# RL6845_IP_SVD register map
Vendor: Realtek
Registers are 32-bit, read-write, reset 0x0 unless marked. A register's access mark holds for its fields unless they carry their own. Offsets are from the block's base; [hi:lo] are bit positions.

## page2
Base 0x40000000
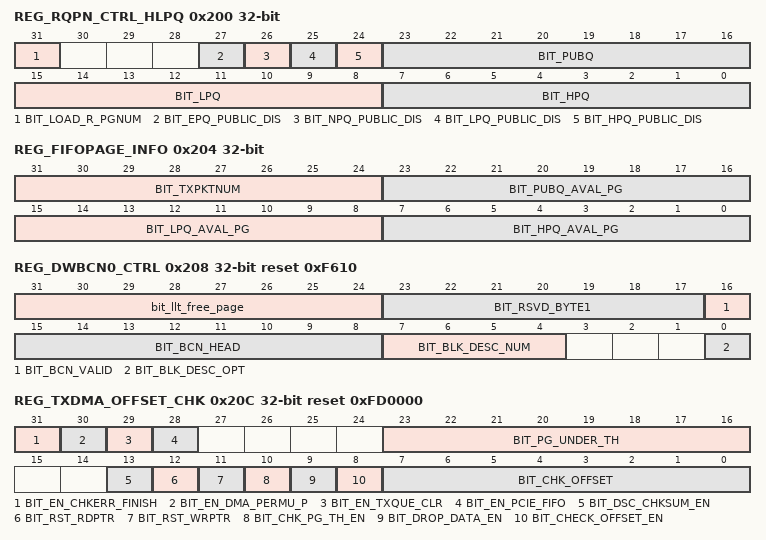
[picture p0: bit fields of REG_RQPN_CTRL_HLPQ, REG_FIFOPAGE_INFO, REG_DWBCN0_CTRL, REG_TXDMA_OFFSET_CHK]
0x200 REG_RQPN_CTRL_HLPQ access per field
  [31] BIT_LOAD_R_PGNUM wo — Write 1 to set RQPN bit[79:0] value to page numbers for initialization
  [27] BIT_EPQ_PUBLIC_DIS rw — When this bit is set, Extra queue available Tx page size excludes the public queue. Otherwise, Extra queue available Tx page size includes public queue
  [26] BIT_NPQ_PUBLIC_DIS rw — When this bit is set, Normal queue available Tx page size excludes the public queue. Otherwise, Normal queue available Tx page size includes public queue
  [25] BIT_LPQ_PUBLIC_DIS rw — When this bit is set, Low queue available Tx page size excludes the public queue. Otherwise, Low queue available Tx page size includes public queue
  [24] BIT_HPQ_PUBLIC_DIS rw — When this bit is set, High queue available Tx page size excludes the public queue. Otherwise, High queue available Tx page size includes public queue
  [23:16] BIT_PUBQ rw — Public Reserved Page Number
  [15:8] BIT_LPQ rw — Low Priority Queue Reserved Page Number
  [7:0] BIT_HPQ rw — High Priority Queue Reserved Page Number
0x204 REG_FIFOPAGE_INFO ro
  [31:24] BIT_TXPKTNUM — Packet number in TXPKTBUF (Normal/Low)
  [23:16] BIT_PUBQ_AVAL_PG — Available Public Queue Page Number
  [15:8] BIT_LPQ_AVAL_PG — Available Low Priority Queue Page Number
  [7:0] BIT_HPQ_AVAL_PG — Available High Priority Queue Page Number
0x208 REG_DWBCN0_CTRL access per field reset 0xF610
  [31:24] bit_llt_free_page ro — RSVD
  [23:17] BIT_RSVD_BYTE1 rw — RSVD
  [16] BIT_BCN_VALID ro — When this bit is set, the beacon packet has finished to write to txpktbuffer. Clear by SW
  [15:8] BIT_BCN_HEAD rw — The head page of packet of Bcnq which is Tx DMA filled Bcnq packet from
  [7:4] BIT_BLK_DESC_NUM rw — The Most Number of Tx Descriptor per Bulk Out Only for USB
  [0] BIT_BLK_DESC_OPT rw — option to select usb descriptor number(according to 0x208[7:4]) 1 : usb_desc_num = 2 * r_blk_desc_num 0 : usb_desc_num = 4 * r_blk_desc_num
0x20C REG_TXDMA_OFFSET_CHK reset 0xFD0000
  [31] BIT_EN_CHKERR_FINISH — Let checksum offload statemachine finish if checksum parser error
  [30] BIT_EN_DMA_PERMU_P — Enable every dma latch fifo ptr for pcie as usb mode as one pkt trans in permu
  [29] BIT_EN_TXQUE_CLR — Enable tx queue clear tx pkt in tde in usb mode
  [28] BIT_EN_PCIE_FIFO — Enable pcie fifo store forward txdesc as before mode
  [23:16] BIT_PG_UNDER_TH — Page threshold value is check by Tx DMA engine.
  [13] BIT_DSC_CHKSUM_EN — Enable SDIO checksum
  [12] BIT_RST_RDPTR — Reset the read pointer of sync FIFO
  [11] BIT_RST_WRPTR — Reset the write pointer of sync FIFO
  [10] BIT_CHK_PG_TH_EN — Enable Tx DMA to check total pages if it is under page threshold
  [9] BIT_DROP_DATA_EN — Enable Tx DMA to drop the redundant data of packet
  [8] BIT_CHECK_OFFSET_EN — Enable Tx DMA to check offset value
  [7:0] BIT_CHK_OFFSET — Offset value is check by Tx DMA engine
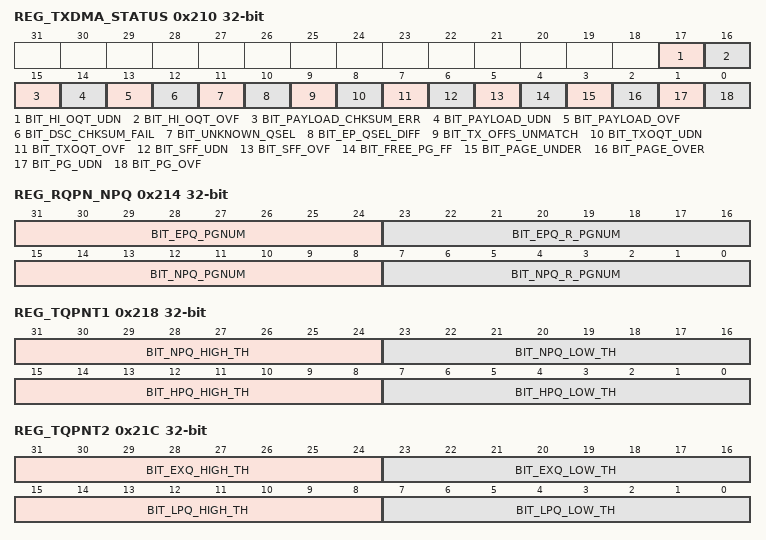
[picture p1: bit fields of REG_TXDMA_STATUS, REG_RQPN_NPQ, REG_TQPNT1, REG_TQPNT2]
0x210 REG_TXDMA_STATUS access per field
  [17] BIT_HI_OQT_UDN ro — High Priority Queue_Tx OQT underflow
  [16] BIT_HI_OQT_OVF ro — High Priority Queue_Tx OQT overflow
  [15] BIT_PAYLOAD_CHKSUM_ERR ro — Payload checksum error
  [14] BIT_PAYLOAD_UDN ro — Payload is under the packet length of Tx descriptor. Clear by SW.
  [13] BIT_PAYLOAD_OVF ro — Payload is over the packet length of Tx descriptor. Clear by SW.
  [12] BIT_DSC_CHKSUM_FAIL ro — Tx descriptor checksum error. Clear by SW.
  [11] BIT_UNKNOWN_QSEL ro — An unknown QSEL of Tx descriptor is detected. Clear by SW.
  [10] BIT_EP_QSEL_DIFF ro — Tx Endpoint is unmatched with the QSEL of descriptor. Clear by SW.
  [9] BIT_TX_OFFS_UNMATCH ro — Tx offset is unmatched. Clear by SW.
  [8] BIT_TXOQT_UDN ro — TXOQT Underflow. Clear by SW.
  [7] BIT_TXOQT_OVF ro — TXOQT Overflow. Clear by SW.
  [6] BIT_SFF_UDN ro — TXDMA Sync FIFO Underflow. Clear by SW.
  [5] BIT_SFF_OVF ro — TXDMA Sync FIFO Overflow. Clear by SW.
  [4] BIT_FREE_PG_FF ro — TXDMA reads NULL page. Clear by SW.
  [3] BIT_PAGE_UNDER ro — Total pages included PTCL un-return pages are under the total reserved pages minus the page threshold. Clear by SW.
  [2] BIT_PAGE_OVER ro — Total pages included PTCL un-return pages are over the total reserved pages. Clear by SW.
  [1] BIT_PG_UDN ro — TXFF page underflow in TDE page controller. Clear by SW.
  [0] BIT_PG_OVF ro — TXFF page overflow in TDE page controller.. Clear by SW.
0x214 REG_RQPN_NPQ access per field
  [31:24] BIT_EPQ_PGNUM ro — Extra Queue Page Number
  [23:16] BIT_EPQ_R_PGNUM rw — Extra Queue Reserved Page Number
  [15:8] BIT_NPQ_PGNUM ro — Normal Priority Queue Page Number
  [7:0] BIT_NPQ_R_PGNUM rw — Normal Priority Queue Reserved Page Number
0x218 REG_TQPNT1
  [31:24] BIT_NPQ_HIGH_TH — For SDIO, Normal Priority Queue Page Number High Threshold
  [23:16] BIT_NPQ_LOW_TH — For SDIO, Normal Priority Queue Page Number Low Threshold
  [15:8] BIT_HPQ_HIGH_TH — For SDIO, High Priority Queue Page Number High Threshold
  [7:0] BIT_HPQ_LOW_TH — For SDIO, High Priority Queue Page Number Low Threshold
0x21C REG_TQPNT2
  [31:24] BIT_EXQ_HIGH_TH — For SDIO, Extra Priority Queue Page Number High Threshold
  [23:16] BIT_EXQ_LOW_TH — For SDIO, Extra Priority Queue Page Number Low Threshold
  [15:8] BIT_LPQ_HIGH_TH — For SDIO, Low Priority Queue Page Number High Threshold
  [7:0] BIT_LPQ_LOW_TH — For SDIO, Low Priority Queue Page Number Low Threshold
0x220 REG_TDE_DEBUG ro
  [31:0] BIT_TDE_DEBUG — tde debug port register.
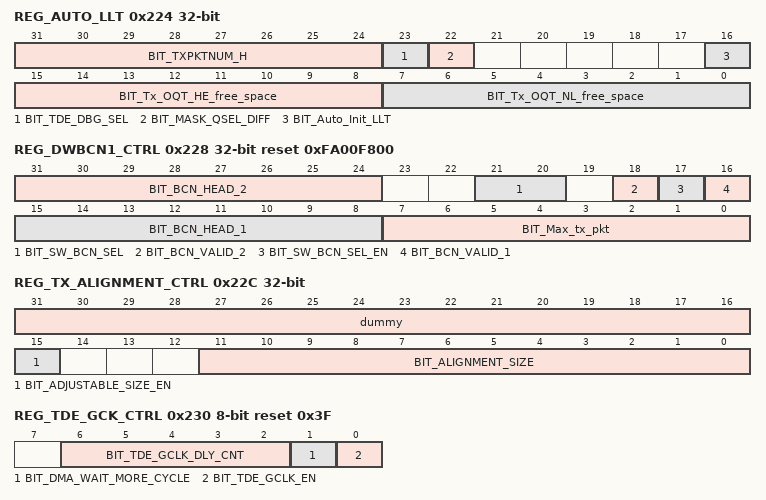
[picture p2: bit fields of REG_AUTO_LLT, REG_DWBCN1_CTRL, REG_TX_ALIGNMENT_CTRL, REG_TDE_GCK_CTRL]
0x224 REG_AUTO_LLT access per field
  [31:24] BIT_TXPKTNUM_H ro — Packet number in TXPKTBUF (High and Extra)
  [23] BIT_TDE_DBG_SEL rw — debug signals selection of Tx DMA
  [22] BIT_MASK_QSEL_DIFF rw — Mask the error bit(tx endpoint is unmatched with qsel, 0x210[10])
  [16] BIT_Auto_Init_LLT rw — Write 1 to enable HW init LLT, driver need polling to 0 meaning init success
  [15:8] BIT_Tx_OQT_HE_free_space ro — High and Extra priority queue
  [7:0] BIT_Tx_OQT_NL_free_space ro — Normal and low priority queue
0x228 REG_DWBCN1_CTRL reset 0xFA00F800
  [31:24] BIT_BCN_HEAD_2 — The head page of packet of Bcnq which is Tx DMA filled Bcnq packet from.
  [21:20] BIT_SW_BCN_SEL — Bcnq head selection from SW setting 2'b01 : r_bcn_head_1 2'b10 : r_bcn_head_2
  [18] BIT_BCN_VALID_2 — When this bit is set, the beacon packet has finished to write to txpktbuffer. Clear by SW.
  [17] BIT_SW_BCN_SEL_EN — Enable Bcnq head selection from SW setting
  [16] BIT_BCN_VALID_1 — When this bit is set, the beacon packet has finished to write to txpktbuffer. Clear by SW.
  [15:8] BIT_BCN_HEAD_1 — The head page of packet of Bcnq which is Tx DMA filled Bcnq packet from.
  [7:0] BIT_Max_tx_pkt — Unit : packet number Max_tx_pkt_for_USB_and_SDIO
0x22C REG_TX_ALIGNMENT_CTRL
  [31:16] dummy
  [15] BIT_ADJUSTABLE_SIZE_EN — Enable tx alignment for sdio. SW can assign the alignment size of blocks in an aggregated-packet.
  [11:0] BIT_ALIGNMENT_SIZE — The alignment size of blocks in an aggregated-packet. Unit: Byte
0x230 REG_TDE_GCK_CTRL 8-bit reset 0x3F
  [6:2] BIT_TDE_GCLK_DLY_CNT — when start trigger of clk gating happens, count for several cycles then disable clk,default:16 cycles
  [1] BIT_DMA_WAIT_MORE_CYCLE — enable this bit,tde_ctl will wait for 16 dma_clk when host dma last data to tde_sync_fifo 1:used for 20M mac clk 0:used for 40M/80M mac clk(will wait for 12 dma_clk)
  [0] BIT_TDE_GCLK_EN — enable this bit,txdma engine will use gated clk
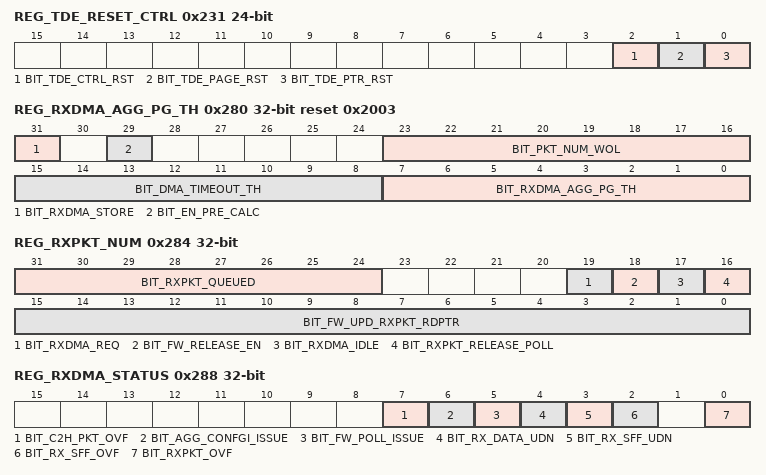
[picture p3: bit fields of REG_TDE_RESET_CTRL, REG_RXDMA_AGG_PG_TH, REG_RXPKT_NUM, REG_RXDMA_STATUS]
0x231 REG_TDE_RESET_CTRL 24-bit wo
  [2] BIT_TDE_CTRL_RST — Write this bit reset FSM of tde_ctrl, ioreg_txfail
  [1] BIT_TDE_PAGE_RST — Write this bit reset FSM of tde_page_cs, ioreg_txfail
  [0] BIT_TDE_PTR_RST — Write this bit reset FSM of tde_ptr_cs, ioreg_txfail
0x234 REG_TQPNT3_V1
0x244 REG_H2C_HEAD
0x280 REG_RXDMA_AGG_PG_TH access per field reset 0x2003
  [31] BIT_RXDMA_STORE rw — usb rx dma old mode store pkt and forward
  [29] BIT_EN_PRE_CALC rw — 0: rde start rxdma when aggregated length over specified threshold; 1: rde start rxdma when next packet, if aggregated, will cause the total length over specified threshold
  [23:16] BIT_PKT_NUM_WOL ro — In wol mode, 8051 should refer this packet counter in RXFF
  [15:8] BIT_DMA_TIMEOUT_TH rw — dma agg timeout time : unit : 32us
  [7:0] BIT_RXDMA_AGG_PG_TH rw — rxdma agg length threshold if sdio : unit 1K, others unit is 4K if use RXDMA_AGG_OLD_MOD in use, unit is 1K
0x284 REG_RXPKT_NUM access per field
  [31:24] BIT_RXPKT_QUEUED ro — The number of packets in RXPKTBUF.
  [19] BIT_RXDMA_REQ ro — rxdma has request
  [18] BIT_FW_RELEASE_EN rw — When this bit is set, RXDMA will enter this mode after on-going RXDMA packet to host completed, and stop DMA packet to host. RXDMA will then report
  [17] BIT_RXDMA_IDLE ro — When RXMA finishes on-going DMA operation, RXMDA will report idle state in this bit. FW can start releasing packets after RXDMA entering idle mode.
  [16] BIT_RXPKT_RELEASE_POLL ro — When this bit is set, RXDMA will decrease RX PKT counter by one. Before this bit is polled, FW shall update RXFF_RD_PTR first.
  [15:0] BIT_FW_UPD_RXPKT_RDPTR rw — FW shall update this register before FW write RXPKT_RELEASE_POLL to 1.
0x288 REG_RXDMA_STATUS access per field
  [7] BIT_C2H_PKT_OVF ro — CH2 pkt overflow. Clr by SW
  [6] BIT_AGG_CONFGI_ISSUE ro — rxdma agg config error. Clr by SW
  [5] BIT_FW_POLL_ISSUE ro — FW Release Poll Error. Clear by SW.
  [4] BIT_RX_DATA_UDN ro — FW Release Poll Error. Clear by SW.
  [3] BIT_RX_SFF_UDN ro — RX Sync FIFO Underflow. Clear by SW.
  [2] BIT_RX_SFF_OVF ro — RX Sync FIFO Overflow. Clear by SW.
  [0] BIT_RXPKT_OVF ro — When RX Packet is more than 255 packets remaining in FF. Clear by SW.
0x28C REG_RXDMA_DPR ro
  [31:0] BIT_RDE_DBG — rde debug port register.
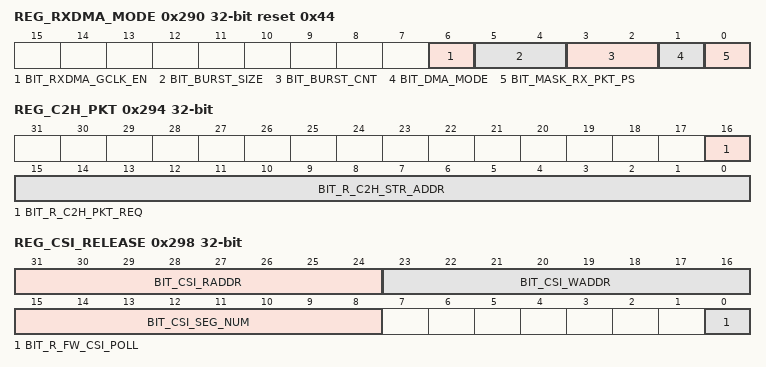
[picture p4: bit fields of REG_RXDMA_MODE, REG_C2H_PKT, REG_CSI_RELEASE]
0x290 REG_RXDMA_MODE reset 0x44
  [6] BIT_RXDMA_GCLK_EN — rxdma_engine clock gating control,1:enable clock gating;0:disable clock gating
  [5:4] BIT_BURST_SIZE — Every burst pkt len 2'b00 : 1KB 2'b01 : 512B 2'b10 : 64B Others : 64B P.S. USB 3.0 must set : 0x00 USB 2.0 High-speed must set : 0x01 USB 2.0 Full-speed must set : 0x10
  [3:2] BIT_BURST_CNT — Burst number in dma mode, support at most 4burst(2'b11) P.S, DD suggest 0x11
  [1] BIT_DMA_MODE — For usb use dma mode; for pcie clr this bit ; for SDIO use Rx DMA Aggregation mode
  [0] BIT_MASK_RX_PKT_PS — RSVD
0x294 REG_C2H_PKT
  [16] BIT_R_C2H_PKT_REQ — C2h packet dma request
  [15:0] BIT_R_C2H_STR_ADDR — C2h packet start address
0x298 REG_CSI_RELEASE access per field
  [31:24] BIT_CSI_RADDR ro — read starting address of next csi segment,8byte unit
  [23:16] BIT_CSI_WADDR ro — write starting address of next csi segment,8byte unit
  [15:8] BIT_CSI_SEG_NUM ro — csi segment number in csibuffer
  [0] BIT_R_FW_CSI_POLL wo
